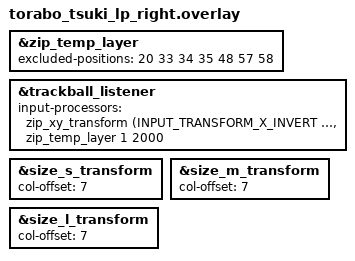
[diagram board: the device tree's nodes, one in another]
#include "torabo_tsuki_lp.dtsi"
#include <input/processors.dtsi>
#include <dt-bindings/zmk/input_transform.h>

&zip_temp_layer {
    excluded-positions = <
        20 // I
        33 // J
        34 // K
        35 // L
        48 // ,
        57 // space left2
        58 // space left3
    >;
};

&trackball_listener {
    input-processors = <
        &zip_xy_transform (INPUT_TRANSFORM_X_INVERT | INPUT_TRANSFORM_Y_INVERT)
        &zip_temp_layer 1 2000
    >;
};

&size_s_transform {
    col-offset = <7>;
};

&size_m_transform {
    col-offset = <7>;
};

&size_l_transform {
    col-offset = <7>;
};
